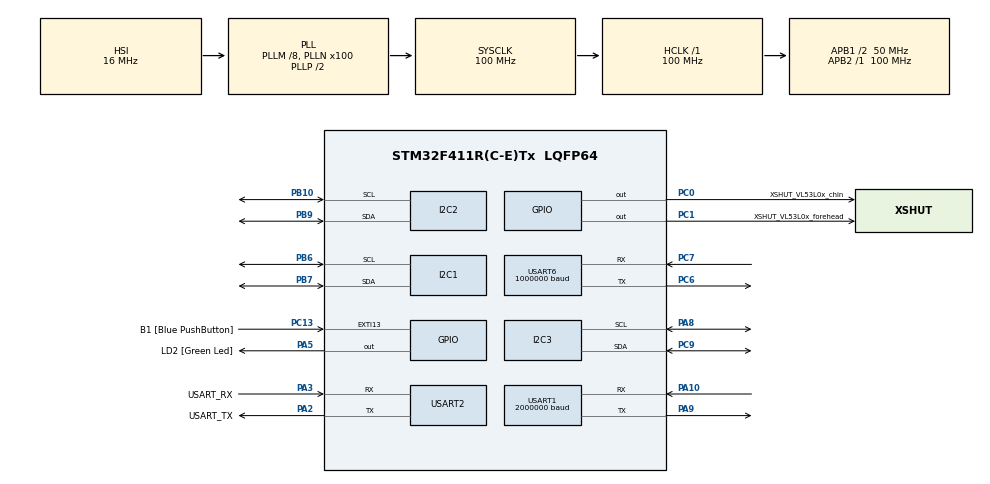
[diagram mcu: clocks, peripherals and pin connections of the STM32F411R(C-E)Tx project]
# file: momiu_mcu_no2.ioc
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Mcu.Family=STM32F4
RCC.CortexFreq_Value=100000000
Dma.USART1_TX.1.MemInc=DMA_MINC_ENABLE
PB10.Mode=I2C
USART1.BaudRate=2000000
PA14.GPIO_Label=TCK
PC0.GPIO_Label=XSHUT_VL53L0x_chin
RCC.SYSCLKSource=RCC_SYSCLKSOURCE_PLLCLK
ProjectManager.StackSize=0x400
PH0\ -\ OSC_IN.Signal=RCC_OSC_IN
RCC.HCLKFreq_Value=100000000
RCC.APB2TimFreq_Value=100000000
PB6.Signal=I2C1_SCL
VP_TIM10_VS_ClockSourceINT.Mode=Enable_Timer
PC7.Signal=USART6_RX
PB6.Mode=I2C
RCC.AHBFreq_Value=100000000
Dma.USART1_RX.0.Priority=DMA_PRIORITY_HIGH
RCC.HSE_VALUE=8000000
PC13-ANTI_TAMP.Signal=GPXTI13
PC14-OSC32_IN.Mode=LSE-External-Oscillator
PA14.Mode=Serial_Wire
PC9.Mode=I2C
PB7.Signal=I2C1_SDA
PA8.Signal=I2C3_SCL
Dma.USART1_RX.0.MemInc=DMA_MINC_ENABLE
Dma.USART1_TX.1.PeriphDataAlignment=DMA_PDATAALIGN_BYTE
RCC.FLatency-AdvancedSettings=FLASH_LATENCY_3
PB9.Signal=I2C2_SDA
Mcu.Package=LQFP64
NVIC.DMA2_Stream7_IRQn=true\:0\:0\:false\:false\:true\:false\:true
USART2.VirtualMode=VM_ASYNC
USART6.VirtualMode=VM_ASYNC
PA2.GPIO_Label=USART_TX
PA10.Signal=USART1_RX
USART6.BaudRate=1000000
Dma.USART1_RX.0.FIFOMode=DMA_FIFOMODE_DISABLE
NVIC.DMA2_Stream2_IRQn=true\:0\:0\:false\:false\:true\:false\:true
Dma.Request1=USART1_TX
RCC.APB1TimFreq_Value=100000000
Dma.USART1_RX.0.Mode=DMA_CIRCULAR
Dma.USART1_TX.1.Priority=DMA_PRIORITY_HIGH
NVIC.USART1_IRQn=true\:0\:0\:false\:false\:true\:true\:true
Dma.Request0=USART1_RX
I2C2.I2C_Mode=I2C_Fast
Dma.USART1_RX.0.Instance=DMA2_Stream2
PA3.Signal=USART2_RX
Dma.USART1_TX.1.Direction=DMA_MEMORY_TO_PERIPH
PB3.GPIO_Label=SWO
TIM10.Prescaler=1000 - 1
PC15-OSC32_OUT.Mode=LSE-External-Oscillator
Dma.USART1_TX.1.Instance=DMA2_Stream7
I2C3.I2C_Mode=I2C_Fast
Dma.USART1_RX.0.PeriphDataAlignment=DMA_PDATAALIGN_BYTE
PA10.Mode=Asynchronous
PC13-ANTI_TAMP.GPIO_Label=B1 [Blue PushButton]
PH1\ -\ OSC_OUT.Mode=HSE-External-Clock-Source
PC6.Signal=USART6_TX
PC0.Signal=GPIO_Output
RCC.APB1CLKDivider=RCC_HCLK_DIV2
PC14-OSC32_IN.Signal=RCC_OSC32_IN
PA13.Signal=SYS_JTMS-SWDIO
PA3.Mode=Asynchronous
PA9.Mode=Asynchronous
PH0\ -\ OSC_IN.Mode=HSE-External-Clock-Source
ProjectManager.TargetToolchain=STM32CubeIDE
I2C1.I2C_Mode=I2C_Fast
PC6.Mode=Asynchronous
Dma.USART1_RX.0.Direction=DMA_PERIPH_TO_MEMORY
PB9.Mode=I2C
PA9.Signal=USART1_TX
Dma.USART1_TX.1.FIFOMode=DMA_FIFOMODE_DISABLE
PC15-OSC32_OUT.Signal=RCC_OSC32_OUT
Dma.USART1_RX.0.PeriphInc=DMA_PINC_DISABLE
PB10.Signal=I2C2_SCL
PA5.Signal=GPIO_Output
PH1\ -\ OSC_OUT.Signal=RCC_OSC_OUT
Dma.USART1_TX.1.MemDataAlignment=DMA_MDATAALIGN_BYTE
board=NUCLEO-F411RE
RCC.VCOOutputFreq_Value=200000000
TIM10.Period=1000 - 1
RCC.APB2Freq_Value=100000000
PC1.GPIO_Label=XSHUT_VL53L0x_forehead
Dma.USART1_RX.0.MemDataAlignment=DMA_MDATAALIGN_BYTE
PA13.Mode=Serial_Wire
Mcu.Name=STM32F411R(C-E)Tx
PA2.Signal=USART2_TX
PA13.GPIO_Label=TMS
RCC.48MHZClocksFreq_Value=50000000
PB3.Signal=SYS_JTDO-SWO
RCC.SYSCLKFreq_VALUE=100000000
PA5.GPIO_Label=LD2 [Green Led]
Dma.USART1_TX.1.Mode=DMA_NORMAL
USART1.VirtualMode=VM_ASYNC
PC13-ANTI_TAMP.GPIO_ModeDefaultEXTI=GPIO_MODE_IT_FALLING
PB7.Mode=I2C
PA14.Signal=SYS_JTCK-SWCLK
ProjectManager.HeapSize=0x200
Dma.USART1_TX.1.PeriphInc=DMA_PINC_DISABLE
NVIC.TIM1_UP_TIM10_IRQn=true\:0\:0\:false\:false\:true\:true\:true
RCC.HSI_VALUE=16000000
NVIC.PriorityGroup=NVIC_PRIORITYGROUP_0
RCC.PLLM=8
RCC.PLLN=100
PA2.Mode=Asynchronous
PA8.Mode=I2C
PC9.Signal=I2C3_SDA
PC7.Mode=Asynchronous
RCC.APB1Freq_Value=50000000
PC1.Signal=GPIO_Output
PA3.GPIO_Label=USART_RX

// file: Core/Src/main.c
/* USER CODE BEGIN Header */
/**
  ******************************************************************************
  * @file           : main.c
  * @brief          : Main program body
  ******************************************************************************
  * @attention
  *
  * <h2><center>&copy; Copyright (c) 2021 STMicroelectronics.
  * All rights reserved.</center></h2>
  *
  * This software component is licensed by ST under BSD 3-Clause license,
  * the "License"; You may not use this file except in compliance with the
  * License. You may obtain a copy of the License at:
  *                        opensource.org/licenses/BSD-3-Clause
  *
  ******************************************************************************
  */
/* USER CODE END Header */
#include "main.h"
#include "dma.h"
#include "i2c.h"
#include "tim.h"
#include "usart.h"
#include "gpio.h"

/* USER CODE BEGIN Includes */
#include "mainpp.h"

/* USER CODE END Includes */

void SystemClock_Config(void);

int main(void)
{

  /* MCU Configuration--------------------------------------------------------*/

  /* Reset of all peripherals, Initializes the Flash interface and the Systick. */
  HAL_Init();

  /* Configure the system clock */
  SystemClock_Config();

  /* Initialize all configured peripherals */
  MX_GPIO_Init();
  MX_DMA_Init();
  MX_USART1_UART_Init();
  MX_USART2_UART_Init();
  MX_I2C1_Init();
  MX_I2C2_Init();
  MX_USART6_UART_Init();
  MX_I2C3_Init();
  MX_TIM10_Init();
  /* USER CODE BEGIN 2 */
  HAL_TIM_Base_Start_IT(&htim10);
  //HAL_TIM_Base_Start_IT(&htim11);

  setup();

  /* USER CODE END 2 */

  /* Infinite loop */
  while (1)
  {

    /* USER CODE BEGIN 3 */
	  loop();
  }
  /* USER CODE END 3 */
}

void SystemClock_Config(void)
{
  RCC_OscInitTypeDef RCC_OscInitStruct = {0};
  RCC_ClkInitTypeDef RCC_ClkInitStruct = {0};

  /** Configure the main internal regulator output voltage
  */
  __HAL_RCC_PWR_CLK_ENABLE();
  __HAL_PWR_VOLTAGESCALING_CONFIG(PWR_REGULATOR_VOLTAGE_SCALE1);
  /** Initializes the RCC Oscillators according to the specified parameters
  * in the RCC_OscInitTypeDef structure.
  */
  RCC_OscInitStruct.OscillatorType = RCC_OSCILLATORTYPE_HSI;
  RCC_OscInitStruct.HSIState = RCC_HSI_ON;
  RCC_OscInitStruct.HSICalibrationValue = RCC_HSICALIBRATION_DEFAULT;
  RCC_OscInitStruct.PLL.PLLState = RCC_PLL_ON;
  RCC_OscInitStruct.PLL.PLLSource = RCC_PLLSOURCE_HSI;
  RCC_OscInitStruct.PLL.PLLM = 8;
  RCC_OscInitStruct.PLL.PLLN = 100;
  RCC_OscInitStruct.PLL.PLLP = RCC_PLLP_DIV2;
  RCC_OscInitStruct.PLL.PLLQ = 4;
  if (HAL_RCC_OscConfig(&RCC_OscInitStruct) != HAL_OK)
  {
    Error_Handler();
  }
  /** Initializes the CPU, AHB and APB buses clocks
  */
  RCC_ClkInitStruct.ClockType = RCC_CLOCKTYPE_HCLK|RCC_CLOCKTYPE_SYSCLK
                              |RCC_CLOCKTYPE_PCLK1|RCC_CLOCKTYPE_PCLK2;
  RCC_ClkInitStruct.SYSCLKSource = RCC_SYSCLKSOURCE_PLLCLK;
  RCC_ClkInitStruct.AHBCLKDivider = RCC_SYSCLK_DIV1;
  RCC_ClkInitStruct.APB1CLKDivider = RCC_HCLK_DIV2;
  RCC_ClkInitStruct.APB2CLKDivider = RCC_HCLK_DIV1;

  if (HAL_RCC_ClockConfig(&RCC_ClkInitStruct, FLASH_LATENCY_3) != HAL_OK)
  {
    Error_Handler();
  }
}

void Error_Handler(void)
{
}

/************************ (C) COPYRIGHT STMicroelectronics *****END OF FILE****/
